VERSION ""

NS_ :

BS_:

BU_:

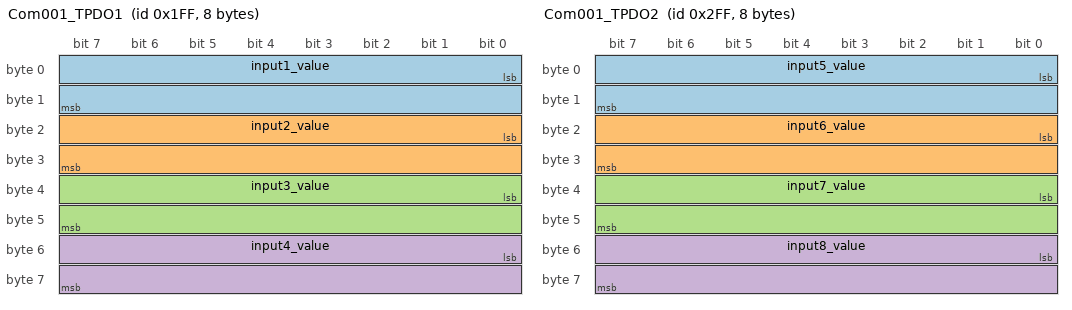
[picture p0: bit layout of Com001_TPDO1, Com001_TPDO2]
BO_ 511 Com001_TPDO1: 8 Vector__XXX
 SG_ input1_value : 0|16@1- (0.001,0) [0|65535] "" Vector__XXX
 SG_ input2_value : 16|16@1- (0.001,0) [0|65535] "" Vector__XXX
 SG_ input3_value : 32|16@1- (0.001,0) [0|65535] "" Vector__XXX
 SG_ input4_value : 48|16@1- (0.001,0) [0|65535] "" Vector__XXX

BO_ 767 Com001_TPDO2: 8 Vector__XXX
 SG_ input5_value : 0|16@1- (0.001,0) [0|65535] "" Vector__XXX
 SG_ input6_value : 16|16@1- (0.001,0) [0|65535] "" Vector__XXX
 SG_ input7_value : 32|16@1- (0.001,0) [0|65535] "" Vector__XXX
 SG_ input8_value : 48|16@1- (0.001,0) [0|65535] "" Vector__XXX

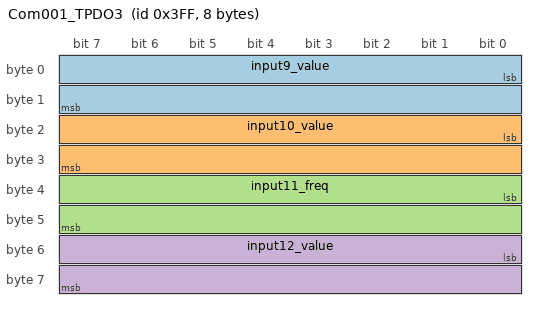
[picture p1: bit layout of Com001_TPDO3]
BO_ 1023 Com001_TPDO3: 8 Vector__XXX
 SG_ input9_value : 0|16@1- (0.001,0) [0|65535] "" Vector__XXX
 SG_ input10_value : 16|16@1- (0.001,0) [0|65535] "" Vector__XXX
 SG_ input11_freq : 32|16@1+ (0.1,0) [0|65535] "Hz" Vector__XXX
 SG_ input12_value : 48|16@1- (0.001,0) [0|65535] "" Vector__XXX

CM_ SG_ 511 input1_value "Generic input 1 value";
CM_ SG_ 511 input2_value "Generic input 2 value";
CM_ SG_ 511 input3_value "Generic input 3 value";
CM_ SG_ 511 input4_value "Generic input 4 value";
CM_ SG_ 767 input5_value "Generic input 5 value";
CM_ SG_ 767 input6_value "Generic input 6 value";
CM_ SG_ 767 input7_value "Generic input 7 value";
CM_ SG_ 767 input8_value "Generic input 8 value";
CM_ SG_ 1023 input9_value "Generic input 9 value";
CM_ SG_ 1023 input10_value "Generic input 10 value";
CM_ SG_ 1023 input11_freq "Generic input 11 (frequency input)";
CM_ SG_ 1023 input12_value "Generic input 12 value";
